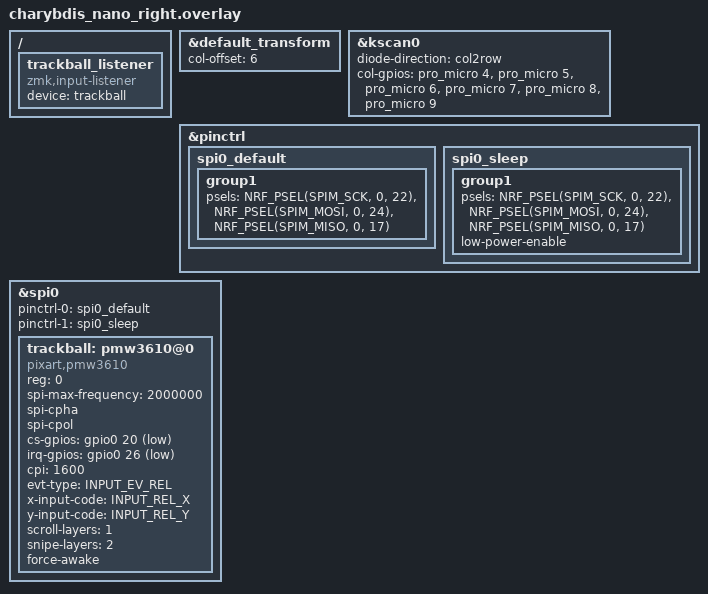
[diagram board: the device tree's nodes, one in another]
 
#include "charybdis_nano.dtsi"
#include <zephyr/dt-bindings/pinctrl/nrf-pinctrl.h>
#include <zephyr/dt-bindings/input/input-event-codes.h>

&default_transform {
    col-offset = <6>;
};

&kscan0 {
    diode-direction = "col2row";
    col-gpios
        = <&pro_micro 4 (GPIO_ACTIVE_HIGH)> // COL0 
        , <&pro_micro 5 (GPIO_ACTIVE_HIGH)> // COL1 
        , <&pro_micro 6 (GPIO_ACTIVE_HIGH)> // COL2 
        , <&pro_micro 7 (GPIO_ACTIVE_HIGH)> // COL3 
        , <&pro_micro 8 (GPIO_ACTIVE_HIGH)> // COL1 
        , <&pro_micro 9 (GPIO_ACTIVE_HIGH)> // COL2 
    ;
    
};

&pinctrl {
    spi0_default: spi0_default {
        group1 {
            psels = <NRF_PSEL(SPIM_SCK, 0, 22)>,
                <NRF_PSEL(SPIM_MOSI, 0, 24)>,
                <NRF_PSEL(SPIM_MISO, 0, 17)>;
        };
    };

    spi0_sleep: spi0_sleep {
        group1 {
            psels = <NRF_PSEL(SPIM_SCK, 0, 22)>,
                <NRF_PSEL(SPIM_MOSI, 0, 24)>,
                <NRF_PSEL(SPIM_MISO, 0, 17)>;
            low-power-enable;
        };
    };
};

&spi0 {
    status = "okay";
    pinctrl-0 = <&spi0_default>;
    pinctrl-1 = <&spi0_sleep>;
    pinctrl-names = "default", "sleep";

    trackball: pmw3610@0 {
        status = "okay";
        compatible = "pixart,pmw3610";
        reg = <0>;
        spi-max-frequency = <2000000>;
        spi-cpha;                          // SPI Mode 3
        spi-cpol;                          // SPI Mode 3
        
        cs-gpios = <&gpio0 20 GPIO_ACTIVE_LOW>;
        irq-gpios = <&gpio0 26 (GPIO_ACTIVE_LOW | GPIO_PULL_UP)>;
        
        // Badjeff driver device properties
        cpi = <1600>;
        evt-type = <INPUT_EV_REL>;
        x-input-code = <INPUT_REL_X>;
        y-input-code = <INPUT_REL_Y>;
        
        // Custom rotation for 45° canted trackball
        // Check if ihlinuxdude fork supports these properties:
        // rotation-deg = <45>;
        // rotate-clockwise;
        
        // Badjeff standard axis properties (fallback orthogonal)
        // swap-xy;         // Uncomment if needed
        // invert-x;        // Uncomment if needed  
        // invert-y;        // Uncomment if needed
        
        // ZMK layer configuration
        scroll-layers = <1>;
        snipe-layers = <2>;
        // automouse-layer = <3>;
        
        // Power management
        force-awake;
    };
};

/ {
    trackball_listener {
        compatible = "zmk,input-listener";
        device = <&trackball>;
    };
};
